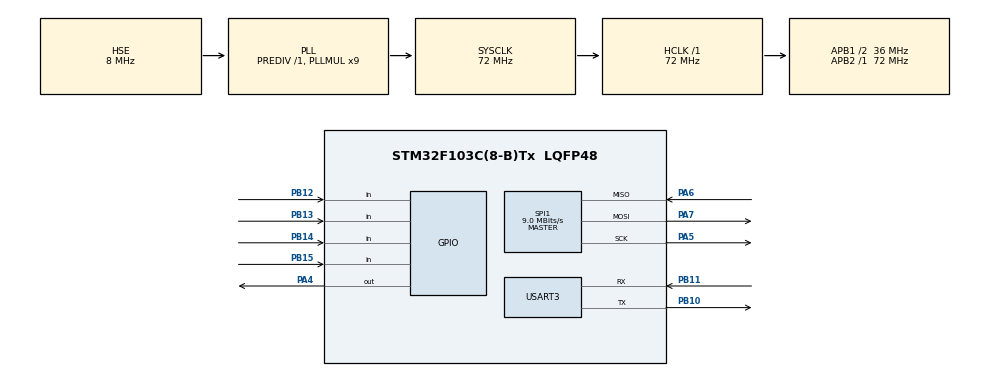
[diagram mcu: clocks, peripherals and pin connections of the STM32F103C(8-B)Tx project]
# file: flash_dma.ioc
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Dma.Request0=SPI1_TX
Dma.Request1=SPI1_RX
Dma.SPI1_RX.1.Direction=DMA_PERIPH_TO_MEMORY
Dma.SPI1_RX.1.Instance=DMA1_Channel2
Dma.SPI1_RX.1.MemDataAlignment=DMA_MDATAALIGN_BYTE
Dma.SPI1_RX.1.MemInc=DMA_MINC_ENABLE
Dma.SPI1_RX.1.Mode=DMA_NORMAL
Dma.SPI1_RX.1.PeriphDataAlignment=DMA_PDATAALIGN_BYTE
Dma.SPI1_RX.1.PeriphInc=DMA_PINC_DISABLE
Dma.SPI1_RX.1.Priority=DMA_PRIORITY_LOW
Dma.SPI1_TX.0.Direction=DMA_MEMORY_TO_PERIPH
Dma.SPI1_TX.0.Instance=DMA1_Channel3
Dma.SPI1_TX.0.MemDataAlignment=DMA_MDATAALIGN_BYTE
Dma.SPI1_TX.0.MemInc=DMA_MINC_ENABLE
Dma.SPI1_TX.0.Mode=DMA_NORMAL
Dma.SPI1_TX.0.PeriphDataAlignment=DMA_PDATAALIGN_BYTE
Dma.SPI1_TX.0.PeriphInc=DMA_PINC_DISABLE
Dma.SPI1_TX.0.Priority=DMA_PRIORITY_LOW
Mcu.Family=STM32F1
Mcu.Name=STM32F103C(8-B)Tx
Mcu.Package=LQFP48
NVIC.DMA1_Channel2_IRQn=true\:1\:0\:true\:false\:true\:false\:true\:true
NVIC.DMA1_Channel3_IRQn=true\:1\:0\:true\:false\:true\:false\:true\:true
NVIC.PriorityGroup=NVIC_PRIORITYGROUP_4
PA13.Mode=Serial_Wire
PA13.Signal=SYS_JTMS-SWDIO
PA14.Mode=Serial_Wire
PA14.Signal=SYS_JTCK-SWCLK
PA4.GPIO_PuPd=GPIO_PULLUP
PA4.Signal=GPIO_Output
PA5.Mode=Full_Duplex_Master
PA5.Signal=SPI1_SCK
PA6.Mode=Full_Duplex_Master
PA6.Signal=SPI1_MISO
PA7.Mode=Full_Duplex_Master
PA7.Signal=SPI1_MOSI
PB10.Mode=Asynchronous
PB10.Signal=USART3_TX
PB11.Mode=Asynchronous
PB11.Signal=USART3_RX
PB12.GPIO_PuPd=GPIO_PULLUP
PB12.Signal=GPIO_Input
PB13.GPIO_PuPd=GPIO_PULLUP
PB13.Signal=GPIO_Input
PB14.GPIO_PuPd=GPIO_PULLUP
PB14.Signal=GPIO_Input
PB15.GPIO_PuPd=GPIO_PULLUP
PB15.Signal=GPIO_Input
PD0-OSC_IN.Mode=HSE-External-Oscillator
PD0-OSC_IN.Signal=RCC_OSC_IN
PD1-OSC_OUT.Mode=HSE-External-Oscillator
PD1-OSC_OUT.Signal=RCC_OSC_OUT
ProjectManager.HeapSize=0x200
ProjectManager.StackSize=0x400
ProjectManager.TargetToolchain=CMake
RCC.AHBFreq_Value=72000000
RCC.APB1CLKDivider=RCC_HCLK_DIV2
RCC.APB1Freq_Value=36000000
RCC.APB1TimFreq_Value=72000000
RCC.APB2Freq_Value=72000000
RCC.APB2TimFreq_Value=72000000
RCC.HCLKFreq_Value=72000000
RCC.PLLMUL=RCC_PLL_MUL9
RCC.PLLSourceVirtual=RCC_PLLSOURCE_HSE
RCC.SYSCLKFreq_VALUE=72000000
RCC.SYSCLKSource=RCC_SYSCLKSOURCE_PLLCLK
RCC.USBFreq_Value=72000000
SPI1.BaudRatePrescaler=SPI_BAUDRATEPRESCALER_8
SPI1.CLKPhase=SPI_PHASE_2EDGE
SPI1.CLKPolarity=SPI_POLARITY_HIGH
SPI1.CalculateBaudRate=9.0 MBits/s
SPI1.Direction=SPI_DIRECTION_2LINES
SPI1.Mode=SPI_MODE_MASTER
SPI1.VirtualType=VM_MASTER
USART3.VirtualMode=VM_ASYNC
board=custom

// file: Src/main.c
/* USER CODE BEGIN Header */
/**
  ******************************************************************************
  * @file           : main.c
  * @brief          : Main program body
  ******************************************************************************
  * @attention
  *
  * Copyright (c) 2025 STMicroelectronics.
  * All rights reserved.
  *
  * This software is licensed under terms that can be found in the LICENSE file
  * in the root directory of this software component.
  * If no LICENSE file comes with this software, it is provided AS-IS.
  *
  ******************************************************************************
  */
/* USER CODE END Header */
#include "main.h"
#include "dma.h"
#include "usart.h"
#include "gpio.h"

/* USER CODE BEGIN Includes */
#include"w25flash.h"
/* USER CODE END Includes */

/* USER CODE BEGIN PD */
#define SIZE 256
/* USER CODE END PD */

void SystemClock_Config(void);

int main(void)
{

  /* MCU Configuration--------------------------------------------------------*/

  /* Reset of all peripherals, Initializes the Flash interface and the Systick. */
  HAL_Init();

  /* Configure the system clock */
  SystemClock_Config();

  /* Initialize all configured peripherals */
  MX_GPIO_Init();
  MX_DMA_Init();
  MX_SPI1_Init();
  MX_USART3_UART_Init();
  /* USER CODE BEGIN 2 */
  uint32_t addr=0;
  uint8_t buf[SIZE];
  /* USER CODE END 2 */

  /* Infinite loop */
  /* USER CODE BEGIN WHILE */
  while (1)
  {
    if(HAL_GPIO_ReadPin(GPIOB,GPIO_PIN_12)==GPIO_PIN_RESET)addr+=SIZE;
    if(!HAL_GPIO_ReadPin(GPIOB,GPIO_PIN_13))addr-=SIZE;
    if(!HAL_GPIO_ReadPin(GPIOB,GPIO_PIN_14)){
      W25Q_WriteDMA(addr,buf,SIZE);
    }
    if(!HAL_GPIO_ReadPin(GPIOB,GPIO_PIN_15)){
      W25Q_ReadDMA(addr,buf,SIZE);
      HAL_UART_Transmit(&huart3,buf,SIZE,HAL_MAX_DELAY);
    }
    HAL_Delay(500);
    /* USER CODE END WHILE */

  }
}

void SystemClock_Config(void)
{
  RCC_OscInitTypeDef RCC_OscInitStruct = {0};
  RCC_ClkInitTypeDef RCC_ClkInitStruct = {0};

  /** Initializes the RCC Oscillators according to the specified parameters
  * in the RCC_OscInitTypeDef structure.
  */
  RCC_OscInitStruct.OscillatorType = RCC_OSCILLATORTYPE_HSE;
  RCC_OscInitStruct.HSEState = RCC_HSE_ON;
  RCC_OscInitStruct.HSEPredivValue = RCC_HSE_PREDIV_DIV1;
  RCC_OscInitStruct.HSIState = RCC_HSI_ON;
  RCC_OscInitStruct.PLL.PLLState = RCC_PLL_ON;
  RCC_OscInitStruct.PLL.PLLSource = RCC_PLLSOURCE_HSE;
  RCC_OscInitStruct.PLL.PLLMUL = RCC_PLL_MUL9;
  if (HAL_RCC_OscConfig(&RCC_OscInitStruct) != HAL_OK)
  {
    Error_Handler();
  }

  /** Initializes the CPU, AHB and APB buses clocks
  */
  RCC_ClkInitStruct.ClockType = RCC_CLOCKTYPE_HCLK|RCC_CLOCKTYPE_SYSCLK
                              |RCC_CLOCKTYPE_PCLK1|RCC_CLOCKTYPE_PCLK2;
  RCC_ClkInitStruct.SYSCLKSource = RCC_SYSCLKSOURCE_PLLCLK;
  RCC_ClkInitStruct.AHBCLKDivider = RCC_SYSCLK_DIV1;
  RCC_ClkInitStruct.APB1CLKDivider = RCC_HCLK_DIV2;
  RCC_ClkInitStruct.APB2CLKDivider = RCC_HCLK_DIV1;

  if (HAL_RCC_ClockConfig(&RCC_ClkInitStruct, FLASH_LATENCY_2) != HAL_OK)
  {
    Error_Handler();
  }
}

void Error_Handler(void)
{
  __disable_irq();
  while (1)
  {
  }
}
